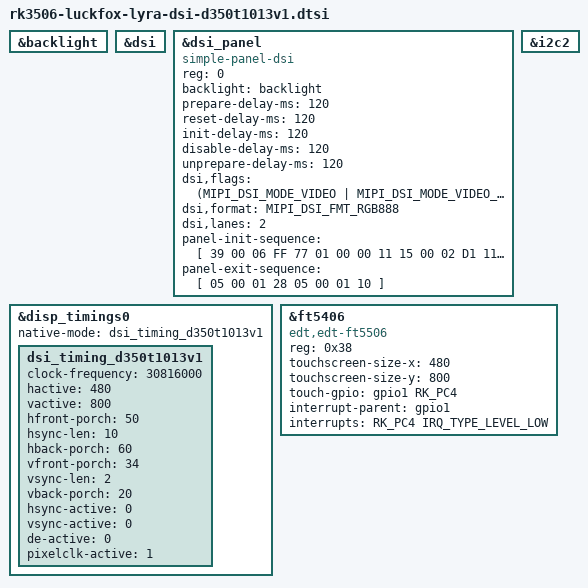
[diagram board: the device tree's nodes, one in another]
/*
* 适用于大显3.5英寸显示屏的设备树配置
* 型号：D350T1013V1
* 分辨率：480 * 800（RGB点阵屏）
* 接口：MIPI DSI（2-lane）
* 驱动：st7701s
* 触摸：有
* 触摸i2c：ft5x06（兼容）
*
* created by: zimolab(https://github.com/zimolab)
* created at: 2025-9-14
*/
/dts-v1/;

#include "rk3506-luckfox-lyra-ultra.dtsi"


// // 背光配置
&backlight{
	status = "okay";
};

// MIPI DSI配置
&dsi {
	status = "okay";
};

&dsi_panel {
	status = "okay";
	compatible = "simple-panel-dsi";
	reg = <0>;
	backlight = <&backlight>;
	
	prepare-delay-ms = <120>;
	reset-delay-ms = <120>;
	init-delay-ms = <120>;
	disable-delay-ms = <120>;
	unprepare-delay-ms = <120>;
	
	dsi,flags = <(MIPI_DSI_MODE_VIDEO | MIPI_DSI_MODE_VIDEO_BURST | MIPI_DSI_MODE_LPM | MIPI_DSI_MODE_NO_EOT_PACKET )>;
	dsi,format = <MIPI_DSI_FMT_RGB888>;
	dsi,lanes  = <2>;
	
	// mipi初始化序列
	panel-init-sequence = [
	39 00 06 FF 77 01 00 00 11
	15 00 02 D1 11
	15 00 02 55 B0
	39 00 06 FF 77 01 00 00 10
	39 00 03 C0 63 00
	39 00 03 C1 09 02
	39 00 03 C2 37 08
	15 00 02 C7 00
	15 00 02 CC 38
	39 00 11 B0 C0 0C 92 0C 10 05 02 0D 07 21 04 53 11 6A 32 1F
	39 00 11 B1 C0 87 CF 0C 10 06 00 03 08 1D 06 54 12 E6 EC 0F
	39 00 06 FF 77 01 00 00 11
	15 00 02 B0 5D
	15 00 02 B1 62
	15 00 02 B2 82
	15 00 02 B3 80
	15 00 02 B5 42
	15 00 02 B7 85
	15 00 02 B8 20
	15 00 02 C0 09
	15 00 02 C1 78
	15 00 02 C2 78
	15 00 02 D0 88
	15 64 02 EE 42
	39 00 04 E0 00 00 02
	39 00 0C E1 04 A0 06 A0 05 A0 07 A0 00 44 44
	39 00 0D E2 00 00 33 33 01 A0 00 00 01 A0 00 00
	39 00 05 E3 00 00 33 33
	39 00 03 E4 44 44
	39 00 11 E5 0C 30 A0 A0 0E 32 A0 A0 08 2C A0 A0 0A 2E A0 A0
	39 00 05 E6 00 00 33 33
	39 00 03 E7 44 44
	39 00 11 E8 0D 31 A0 A0 0F 33 A0 A0 09 2D A0 A0 0B 2F A0 A0
	39 00 08 EB 00 01 E4 E4 44 88 00
	39 00 11 ED FF F5 47 6F 0B A1 A2 BF FB 2A 1A B0 F6 74 5F FF
	15 00 02 EE 42
	39 00 06 FF 77 01 00 00 00
	15 00 02 36 00
	15 00 02 3A 70
	05 C8 01 11
	05 32 01 29
	];
	
	// 面板退出序列
	panel-exit-sequence = [
	05 00 01 28
	05 00 01 10
	];
	
};

&disp_timings0 {
	native-mode = <&dsi_timing_d350t1013v1>;
	
	dsi_timing_d350t1013v1: dsi_timing_d350t1013v1 {
		clock-frequency = <30816000>;// 时钟频率
		hactive = <480>;// 水平像素
		vactive = <800>;// 垂直像素
		hfront-porch = <50>;// 水平前廊
		hsync-len = <10>;// 水平同步长度
		hback-porch = <60>;// 水平后廊
		vfront-porch = <34>;// 垂直前廊
		vsync-len = <2>;// 垂直同步长度
		vback-porch = <20>;// 垂直后廊
		hsync-active = <0>;// 水平同步极性激活
		vsync-active = <0>;// 垂直同步极性激活
		de-active = <0>;// 数据使能极性激活
		pixelclk-active = <1>;// 像素时钟极性激活
	};
};

&i2c2{
	status = "okay";
};


/*
* 触摸IC所在I2C总线：I2C2
* 触摸IC地址：0x38
* 触摸IC兼容驱动：edt-ft5506
* 触摸IC中断引脚：GPIO1_C4
*/
&ft5406{
	status = "okay";
	compatible = "edt,edt-ft5506";
	reg = <0x38>;
	
	/delete-property/ touchscreen-inverted-x;
	/delete-property/ touchscreen-inverted-y;
	/delete-property/ touchscreen-swapped-x-y;	
	
	touchscreen-size-x = <480>;
	touchscreen-size-y = <800>;
	
	touch-gpio = <&gpio1 RK_PC4 IRQ_TYPE_EDGE_RISING>;
	interrupt-parent = <&gpio1>;
	interrupts = <RK_PC4 IRQ_TYPE_LEVEL_LOW>;
	
};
